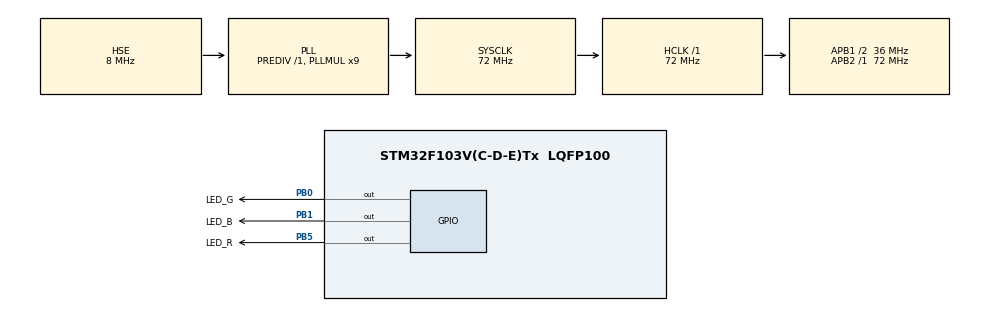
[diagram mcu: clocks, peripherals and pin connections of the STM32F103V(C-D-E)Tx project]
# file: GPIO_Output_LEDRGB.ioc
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Mcu.Family=STM32F1
Mcu.Name=STM32F103V(C-D-E)Tx
Mcu.Package=LQFP100
NVIC.PriorityGroup=NVIC_PRIORITYGROUP_4
OSC_IN.Mode=HSE-External-Oscillator
OSC_IN.Signal=RCC_OSC_IN
OSC_OUT.Mode=HSE-External-Oscillator
OSC_OUT.Signal=RCC_OSC_OUT
PA13.Mode=JTAG_5_pins
PA13.Signal=SYS_JTMS-SWDIO
PA14.Mode=JTAG_5_pins
PA14.Signal=SYS_JTCK-SWCLK
PA15.Mode=JTAG_5_pins
PA15.Signal=SYS_JTDI
PB0.GPIO_Label=LED_G
PB0.GPIO_Speed=GPIO_SPEED_FREQ_HIGH
PB0.PinState=GPIO_PIN_SET
PB0.Signal=GPIO_Output
PB1.GPIO_Label=LED_B
PB1.GPIO_Speed=GPIO_SPEED_FREQ_HIGH
PB1.PinState=GPIO_PIN_SET
PB1.Signal=GPIO_Output
PB3.Mode=JTAG_5_pins
PB3.Signal=SYS_JTDO-TRACESWO
PB4.Mode=JTAG_5_pins
PB4.Signal=SYS_NJTRST
PB5.GPIO_Label=LED_R
PB5.GPIO_Speed=GPIO_SPEED_FREQ_HIGH
PB5.PinState=GPIO_PIN_SET
PB5.Signal=GPIO_Output
PC14-OSC32_IN.Mode=LSE-External-Oscillator
PC14-OSC32_IN.Signal=RCC_OSC32_IN
PC15-OSC32_OUT.Mode=LSE-External-Oscillator
PC15-OSC32_OUT.Signal=RCC_OSC32_OUT
ProjectManager.HeapSize=0x200
ProjectManager.StackSize=0x400
ProjectManager.TargetToolchain=MDK-ARM V5.27
RCC.AHBFreq_Value=72000000
RCC.APB1CLKDivider=RCC_HCLK_DIV2
RCC.APB1Freq_Value=36000000
RCC.APB1TimFreq_Value=72000000
RCC.APB2Freq_Value=72000000
RCC.APB2TimFreq_Value=72000000
RCC.HCLKFreq_Value=72000000
RCC.PLLMUL=RCC_PLL_MUL9
RCC.PLLSourceVirtual=RCC_PLLSOURCE_HSE
RCC.SYSCLKFreq_VALUE=72000000
RCC.SYSCLKSource=RCC_SYSCLKSOURCE_PLLCLK
RCC.USBFreq_Value=72000000
board=custom

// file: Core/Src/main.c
/* USER CODE BEGIN Header */
/**
  ******************************************************************************
  * @file           : main.c
  * @brief          : Main program body
  ******************************************************************************
  * @attention
  *
  * <h2><center>&copy; Copyright (c) 2021 STMicroelectronics.
  * All rights reserved.</center></h2>
  *
  * This software component is licensed by ST under BSD 3-Clause license,
  * the "License"; You may not use this file except in compliance with the
  * License. You may obtain a copy of the License at:
  *                        opensource.org/licenses/BSD-3-Clause
  *
  ******************************************************************************
  */
/* USER CODE END Header */
#include "main.h"
#include "led_rgb.h"

void SystemClock_Config(void);

int main(void)
{

  /* MCU Configuration--------------------------------------------------------*/

  /* Reset of all peripherals, Initializes the Flash interface and the Systick. */
  HAL_Init();

  /* Configure the system clock */
  SystemClock_Config();

  /* Initialize all configured peripherals */
  MX_GPIO_Init();

  /* USER CODE BEGIN 2 */
  HAL_GPIO_WritePin(LED_R_GPIO_Port,LED_R_Pin,GPIO_PIN_RESET);  // HAL_GPIO_WritePin 引脚写状态：GPIO_PIN_RESET，GPIO_PIN_SET
  HAL_Delay(1000);
  HAL_GPIO_TogglePin(LED_R_GPIO_Port,LED_R_Pin);    // HAL_GPIO_TogglePin 引脚状态翻转

  LED_Color_TypeDef Led_Color = LED_BLUE;           // RGB颜色枚举
  Led_Toggle(LED_GPIO_Port,Led_SetColor(Led_Color));
  HAL_Delay(1000);
  /* USER CODE END 2 */

  /* Infinite loop */
  while (1)
  {
    Led_Set(LED_GPIO_Port,Led_Next_Color());
    HAL_Delay(500);

  }
}

void SystemClock_Config(void)
{
  RCC_OscInitTypeDef RCC_OscInitStruct = {0};
  RCC_ClkInitTypeDef RCC_ClkInitStruct = {0};

  /** Initializes the RCC Oscillators according to the specified parameters
  * in the RCC_OscInitTypeDef structure.
  */
  RCC_OscInitStruct.OscillatorType = RCC_OSCILLATORTYPE_HSE;
  RCC_OscInitStruct.HSEState = RCC_HSE_ON;
  RCC_OscInitStruct.HSEPredivValue = RCC_HSE_PREDIV_DIV1;
  RCC_OscInitStruct.HSIState = RCC_HSI_ON;
  RCC_OscInitStruct.PLL.PLLState = RCC_PLL_ON;
  RCC_OscInitStruct.PLL.PLLSource = RCC_PLLSOURCE_HSE;
  RCC_OscInitStruct.PLL.PLLMUL = RCC_PLL_MUL9;
  if (HAL_RCC_OscConfig(&RCC_OscInitStruct) != HAL_OK)
  {
    Error_Handler();
  }
  /** Initializes the CPU, AHB and APB buses clocks
  */
  RCC_ClkInitStruct.ClockType = RCC_CLOCKTYPE_HCLK|RCC_CLOCKTYPE_SYSCLK
                              |RCC_CLOCKTYPE_PCLK1|RCC_CLOCKTYPE_PCLK2;
  RCC_ClkInitStruct.SYSCLKSource = RCC_SYSCLKSOURCE_PLLCLK;
  RCC_ClkInitStruct.AHBCLKDivider = RCC_SYSCLK_DIV1;
  RCC_ClkInitStruct.APB1CLKDivider = RCC_HCLK_DIV2;
  RCC_ClkInitStruct.APB2CLKDivider = RCC_HCLK_DIV1;

  if (HAL_RCC_ClockConfig(&RCC_ClkInitStruct, FLASH_LATENCY_2) != HAL_OK)
  {
    Error_Handler();
  }
}

void Error_Handler(void)
{
  __disable_irq();
  while (1)
  {
  }
}

/************************ (C) COPYRIGHT STMicroelectronics *****END OF FILE****/
